# N572F065_v3 register map
File version: 1.0
Registers are 32-bit, read-write, reset 0x0 unless marked. A register's access mark holds for its fields unless they carry their own. Offsets are from the block's base; [hi:lo] are bit positions.

## SYS — SYS Register Map
Base 0x50000000
0x00 SYS_PDID ro reset 0xF064 — Product Identifier Register
  [31:0] PDID — Product Identifier. Chip identifier (part number) for N572F064 series.
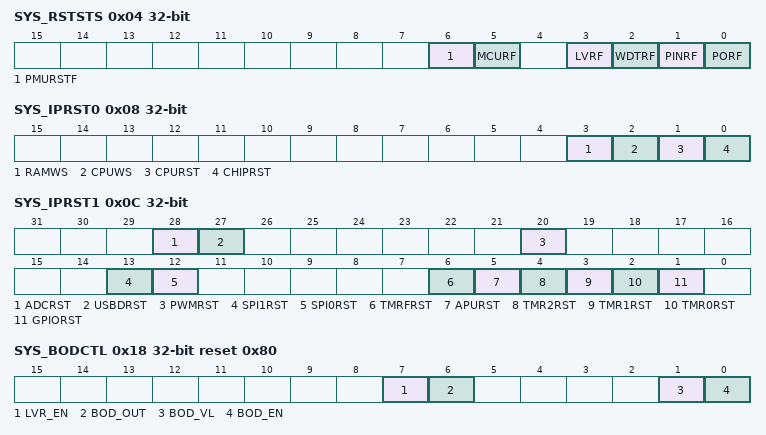
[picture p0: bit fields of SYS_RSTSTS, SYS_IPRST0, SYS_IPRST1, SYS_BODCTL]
0x04 SYS_RSTSTS (reset mask 0xFFFFFF00) — System Reset Source Register
  [6] PMURSTF — Reset Source From PMU. The PMURSTF flag is set by the reset signal from the PMU module to indicate the previous reset source. Note: Write 1 to clear this bit to 0.
    0=No reset from PMU; 1=The PMU has issued the reset signal to reset the system
  [5] MCURF — MCU Reset Flag. The MCURF flag is set by the "reset signal" from the MCU Cortex_M0 module to indicate the previous reset source. Note: Write 1 to clear this bit to 0.
    0=No reset from MCU; 1=The MCU Cortex_M0 had issued the reset signal to reset the system
  [3] LVRF — LVR Reset Flag. The LVR reset flag is set by the "Reset Signal" from the Low Voltage Reset Controller to indicate the previous reset source. Note: Write 1 to clear this bit to 0.
    0=No reset from LVR; 1=LVR controller had issued the reset signal to reset the system
  [2] WDTRF — Reset Source From WDG. The WDTRF flag is set if pervious reset source originates from the Watch-Dog module. Note: Write 1 to clear this bit to 0.
    0=No reset from Watch-Dog; 1=The Watch-Dog module issued the reset signal to reset the system
  [1] PINRF — nRESET Pin Reset Flag. The nRESET pin reset flag is set by the "Reset Signal" from the nRESET Pin to indicate the previous reset source. Note: Write 1 to clear this bit to 0.
    0=No reset from nRESET pin; 1=Pin nRESET had issued the reset signal to reset the system
  [0] PORF — POR Reset Flag. The POR reset flag is set by the "Reset Signal" from the Power-on Reset (POR) Controller to indicate the previous reset source. Note: Write 1 to clear this bit to 0.
    0=No reset from POR; 1=Power-on Reset (POR) Controller had issued the reset signal to reset the system
0x08 SYS_IPRST0 — IP Reset Control Resister0
  [3] RAMWS — Wait State Control For CPU Access RAM
    0=1 HCLK clock wait-state; 1=zero wait-state
  [2] CPUWS — CPU Wait-State Control For Flash Memory Access. Note: that CPUWS cannot be set as "1" when CPU runs the program to do Flash ISP operation.
    0=1 HCLK clock wait-state; 1=zero wait-state
  [1] CPURST — CPU Kernel One Shot Reset. Setting this bit will reset the CPU kernel and Flash Memory Controller(FMC), this bit will automatically return to "0" after the 2 clock cycles
    0=Normal; 1=Reset CPU
  [0] CHIPRST — CHIP One Shot Reset. Set this bit will reset the whole chip, this bit will automatically return to "0" after 2 clock cycles. The CHIPRST is almost the same as the POR reset, all the chip modules are reset but the chip settings from flash are not reloaded.
    0=Normal; 1=Reset CHIP
0x0C SYS_IPRST1 — IP Reset Control Resister1
  [28] ADCRST — ADC Controller Reset
    0=Normal Operation; 1=IP reset
  [27] USBDRST — USB Device Controller Reset
    0=Normal operation; 1=IP reset
  [20] PWMRST — PWM Controller Reset
    0=Normal Operation; 1=IP reset
  [13] SPI1RST — SPI1 Controller Reset
    0=Normal Operation; 1=IP reset
  [12] SPI0RST — SPI0 Controller Reset
    0=Normal Operation; 1=IP reset
  [6] TMRFRST — TimerF Controller Reset
    0=Normal operation; 1=IP reset
  [5] APURST — APU Controller Reset
    0=Normal operation; 1=IP reset
  [4] TMR2RST — Timer2 Controller Reset
    0=Normal operation; 1=IP reset
  [3] TMR1RST — Timer1 Controller Reset
    0=Normal Operation; 1=IP reset
  [2] TMR0RST — Timer0 Controller Reset
    0=Normal Operation; 1=IP reset
  [1] GPIORST — GPIO Controller Reset
    0=Normal operation; 1=IP reset
0x18 SYS_BODCTL reset 0x80 — Brown-Out Detector Control Register
  [7] LVR_EN — Low Voltage Reset (LVR) Enable (Protected Bit). The LVR function resets the chip when the input power voltage is lower than LVR circuit setting. LVR function is enabled in default.
    0=Disable LVR function; 1=Enable LVR function - After enable the bit, the LVR function will active with 100uS delay for LVR output stable
  [6] BOD_OUT — The Status For Brown-Out Detector Output It's a read only bit.
    0=The detected voltage is lower than BOD_VL setting. If the BOD_EN is "0", this bit always responses "0"; 1=The detected voltage is higher than BOD_VL setting
  [1] BOD_VL — Brown-Out Detector Threshold Voltage Selection (Initiate & Protected Bit). The default value is set by flash controller user configuration register CONFIG[21].
    0=Threshold voltage is 2.7V; 1=Threshold voltage is 3.0V
  [0] BOD_EN — Brown-Out Detector Enable (Initiated & Protected Bit)
    0=Brown-Out Detector function is disabled; 1=Brown-Out Detector function is enabled,
0x1C SYS_PORCTL — Power-On-Reset Controller Register
  [15:0] POROFF — Power-On Reset Enable Bit (Write Protect). When powered on, the POR circuit generates a reset signal to reset the whole chip function, but noise on the power may cause the POR active again. User can disable internal POR circuit to avoid unpredictable noise to cause chip reset by writing 0x5AA5 to this field. The POR function will be active again when this field is set to another value or chip is reset by other reset source, including: nRESET, Watchdog, LVR reset, ICE reset command and the software-chip reset function.
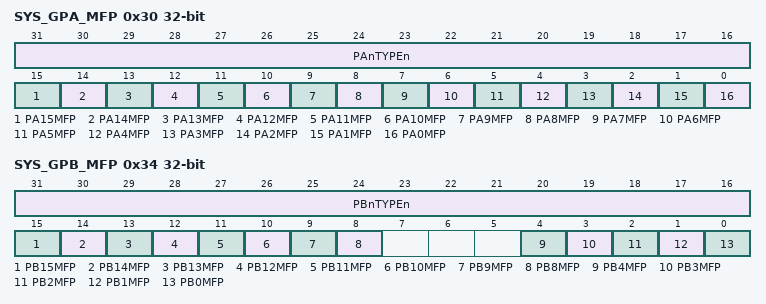
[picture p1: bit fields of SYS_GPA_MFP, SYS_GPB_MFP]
0x30 SYS_GPA_MFP — GPIO PA Multiple Alternate Functions and Input Type Control Register
  [31:16] PAnTYPEn
    0=PA.n I/O cell input Schmitt Trigger function is disabled; 1=PA.n I/O cell input Schmitt Trigger function is enabled
  [15] PA15MFP
    0=The GPIOA-15 is selected to the pin PA.15; 1=ADC input channel 7
  [14] PA14MFP
    0=The GPIOA-14 is selected to the pin PA.14; 1=ADC input channel 6
  [13] PA13MFP
    0=The GPIOA-13 is selected to the pin PA.13; 1=ADC input channel 5
  [12] PA12MFP
    0=The GPIOA-12 is selected to the pin PA.12; 1=ADC input channel 4
  [11] PA11MFP
    0=The GPIOA-11 is selected to the pin PA.11; 1=ADC input channel 3
  [10] PA10MFP
    0=The GPIOA-10 is selected to the pin PA.10; 1=ADC input channel 2
  [9] PA9MFP
    0=The GPIOA-9 is selected to the pin PA.9; 1=ADC input channel 1
  [8] PA8MFP
    0=The GPIOA-8 is selected to the pin PA.8; 1=ADC input channel 0
  [7] PA7MFP
    0=The GPIOA-7 is selected to the pin PA.7; 1=ADC input external trigger input
  [6] PA6MFP
    0=The GPIOA-6 is selected to the pin PA.6; 1=External interrupt input
  [5] PA5MFP
    0=The GPIOA-5 is selected to the pin PA.5; 1=Timer0 counter external input
  [4] PA4MFP
    0=The GPIOA-4 is selected to the pin PA.4; 1=SPI0 data output
  [3] PA3MFP
    0=The GPIOA-3 is selected to the pin PA.3; 1=SPI0 data input
  [2] PA2MFP
    0=The GPIOA-2 is selected to the pin PA.2; 1=SPI0 clock output
  [1] PA1MFP
    0=The GPIOA-1 is selected to the pin PA.1; 1=SPI0 1st chip select output
  [0] PA0MFP
    0=The GPIOA-0 is selected to the pin PA.0; 1=SPI0 2nd chip select output
0x34 SYS_GPB_MFP — GPIO PB Multiple Alternate Functions and Input Type Control Register
  [31:16] PBnTYPEn
    0=PB.n I/O cell input Schmitt Trigger function is disabled; 1=PB.n I/O cell input Schmitt Trigger function is enabled
  [15] PB15MFP
    0=The GPIOB-15 is selected to the pin PB.15; 1=Timer2 counter external input
  [14] PB14MFP
    0=The GPIOB-14 is selected to the pin PB.14; 1=Timer1 counter external input
  [13] PB13MFP
    0=The GPIOB-13 is selected to the pin PB.13; 1=IR carrier output
  [12] PB12MFP
    0=The GPIOB-12 is selected to the pin PB.12; 1=PWM timer capture input
  [11] PB11MFP
    0=The GPIOB-11 is selected to the pin PB.11; 1=PWM output pin 3
  [10] PB10MFP
    0=The GPIOB-10 is selected to the pin PB.10; 1=PWM output pin 2
  [9] PB9MFP
    0=The GPIOB-9 is selected to the pin PB.9; 1=PWM output pin 1
  [8] PB8MFP
    0=The GPIOB-8 is selected to the pin PB.8; 1=PWM output pin 0
  [4] PB4MFP
    0=The GPIOB-4 is selected to the pin PB.4; 1=SPI1 data output/input
  [3] PB3MFP
    0=The GPIOB-3 is selected to the pin PB.3; 1=SPI1 data input/output
  [2] PB2MFP
    0=The GPIOB-2 is selected to the pin PB.2; 1=SPI1 clock output/input
  [1] PB1MFP
    0=The GPIOB-1 is selected to the pin PB.1; 1=SPI1 1st chip select output or slave select input
  [0] PB0MFP
    0=The GPIOB-0 is selected to the pin PB.0; 1=SPI1 2nd chip select output
0x100 SYS_REGLCTL — Register Lock Control Register
  [0] REGLCTL ro — Protected Register Lock/Unlock Index (Read Only). SPI0_RCLK - address 0x4003_0030. FMC_ISPCTL - address 0x5000_C000 (Flash ISP Control register). WDT_CTL - address 0x4000_4000. FATCON - address 0x5000_C018
    0=Protected registers are locked. Any write to the target register is ignored; 1=Protected registers are unlocked
  [7:0] SYS_REGLCTL wo — Register Lock Control Code (Write Only). Some registers have write-protection function. Writing these registers have to disable the protected function by writing the sequence value "59h", "16h", "88h" to this field. After this sequence is completed, the REGLCTL bit will be set to 1 and write-protection registers can be normal write.
